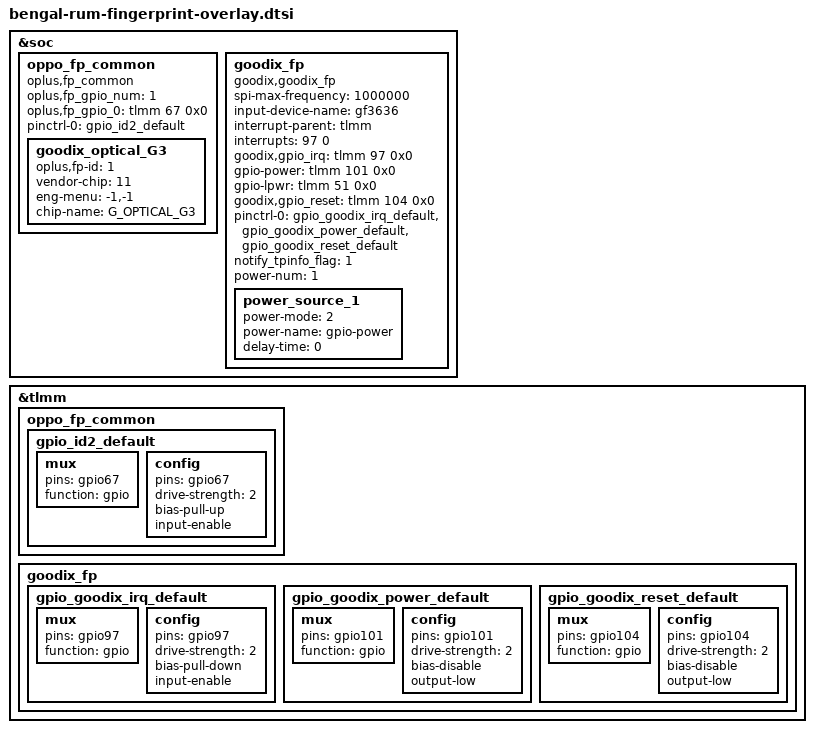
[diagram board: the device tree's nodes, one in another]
// SPDX-License-Identifier: GPL-2.0-only
/*
 * Copyright (C) 2018-2020 Oplus. All rights reserved.
 */
&soc {
	oppo_fp_common {
		compatible = "oplus,fp_common";
        oplus,fp_gpio_num = <1>;
        oplus,fp_gpio_0 = <&tlmm 67 0x0>;
		pinctrl-names = "default";
		pinctrl-0 = <&gpio_id2_default>;
		goodix_optical_G3 {
			oplus,fp-id = <1>; /* fp id mapping table */
			vendor-chip = <11>; /* please refer to the struct fp_vendor_t in oppo_fp_commmon.n */
			eng-menu = "-1,-1"; /* represents SNR, inclination test item in engineer menu, and 0/1 means off/on */
			chip-name = "G_OPTICAL_G3";  /* /proc/fp_id, will be displayed in engineer menu  */
		};
	};
	goodix_fp {
		status = "ok";
		compatible = "goodix,goodix_fp";
        	spi-max-frequency = <1000000>;
		input-device-name = "gf3636";
		interrupt-parent = <&tlmm>;
		interrupts = <97 0>;
		goodix,gpio_irq = <&tlmm 97 0x0>;
		gpio-power = <&tlmm 101 0x0>;
		gpio-lpwr = <&tlmm 51 0x0>;
		goodix,gpio_reset = <&tlmm 104 0x0>;
        pinctrl-names = "default";
        pinctrl-0 = <&gpio_goodix_irq_default>, <&gpio_goodix_power_default>, <&gpio_goodix_reset_default>;

		notify_tpinfo_flag = <1>;
		power-num = <1>;
		power_source_1 {
			power-mode = <2>;
			power-name = "gpio-power";
			delay-time = <0>;
		};
	};
};

&tlmm {
	//#ifdef OPLUS_FEATURE_FINGERPRINT
	oppo_fp_common{
		gpio_id2_default: gpio_id2_default {
			mux {
				pins = "gpio67";
				function = "gpio";
			};
			config {
				pins = "gpio67";
				drive-strength = <2>;
				bias-pull-up;
				input-enable;
			};
		};
	};

	goodix_fp{
        gpio_goodix_irq_default: gpio_goodix_irq_default {
            mux {
                pins = "gpio97";
                function = "gpio";
            };
            config {
                pins = "gpio97";
                drive-strength = <2>;
                bias-pull-down;
                input-enable;
            };
        };
        gpio_goodix_power_default: gpio_goodix_power_default {
            mux {
                pins = "gpio101";
                function = "gpio";
            };
            config {
                pins = "gpio101";
                drive-strength = <2>;
                bias-disable;
                output-low;
            };
        };
        gpio_goodix_reset_default: gpio_goodix_reset_default {
            mux {
                pins = "gpio104";
                function = "gpio";
            };
            config {
                pins = "gpio104";
                drive-strength = <2>;
                bias-disable;
                output-low;
            };
        };
	};
};
